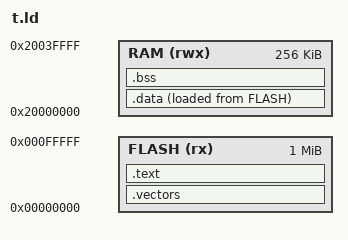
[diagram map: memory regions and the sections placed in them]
/* Generated by silicac from board.soc.memory (§6.4) — do not edit. */
MEMORY
{
  FLASH (rx) : ORIGIN = 0x00000000, LENGTH = 1048576
  RAM  (rwx) : ORIGIN = 0x20000000, LENGTH = 262144
}
ENTRY(Reset_Handler)
_estack = ORIGIN(RAM) + LENGTH(RAM);
SECTIONS
{
  .vectors : { KEEP(*(.vectors)) } > FLASH
  .text    : { *(.text*) *(.rodata*) } > FLASH
  _sidata = LOADADDR(.data);
  .data : { _sdata = .; *(.data*) _edata = .; } > RAM AT > FLASH
  .bss  : { _sbss = .; *(.bss*) *(COMMON) _ebss = .; } > RAM
  /DISCARD/ : { *(.ARM.exidx*) *(.ARM.extab*) }
}
